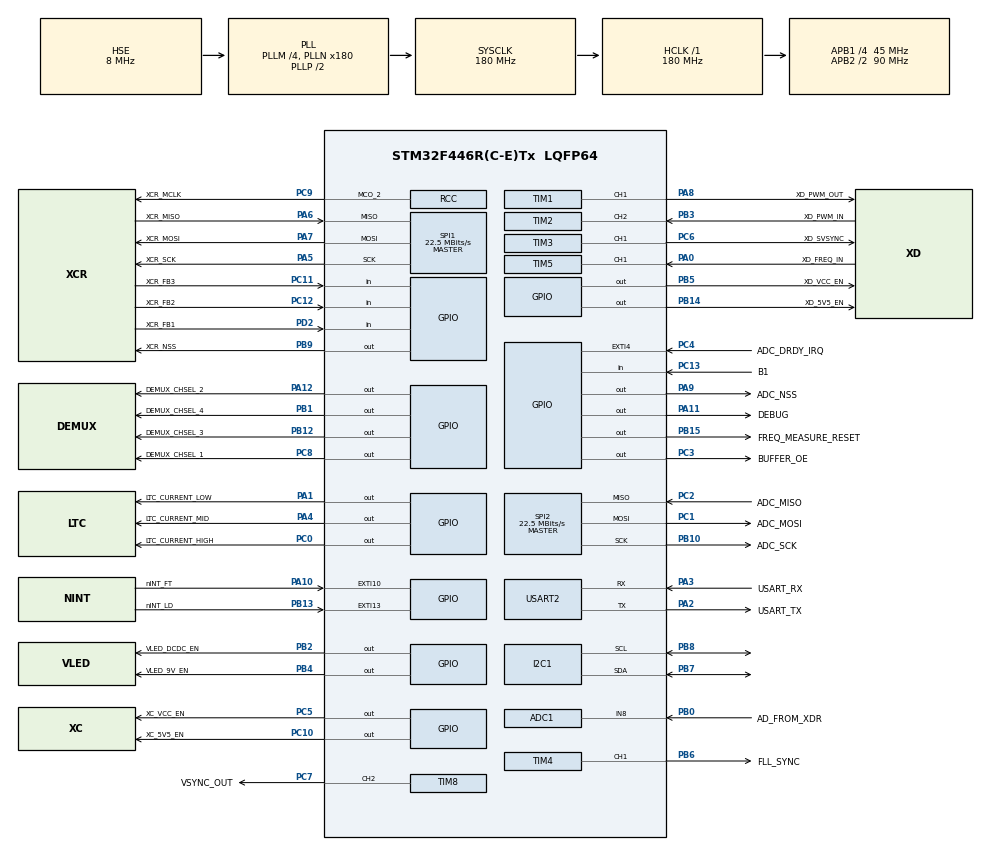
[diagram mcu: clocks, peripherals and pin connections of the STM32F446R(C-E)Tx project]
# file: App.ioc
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ADC1.Channel-0\#ChannelRegularConversion=ADC_CHANNEL_8
ADC1.NbrOfConversionFlag=1
ADC1.Rank-0\#ChannelRegularConversion=1
ADC1.SamplingTime-0\#ChannelRegularConversion=ADC_SAMPLETIME_480CYCLES
ADC1.master=1
Dma.Request0=SPI1_TX
Dma.Request1=TIM1_CH1
Dma.Request2=TIM2_CH2/CH4
Dma.Request3=TIM5_CH1
Dma.SPI1_TX.0.Direction=DMA_MEMORY_TO_PERIPH
Dma.SPI1_TX.0.FIFOMode=DMA_FIFOMODE_DISABLE
Dma.SPI1_TX.0.Instance=DMA2_Stream3
Dma.SPI1_TX.0.MemDataAlignment=DMA_MDATAALIGN_HALFWORD
Dma.SPI1_TX.0.MemInc=DMA_MINC_ENABLE
Dma.SPI1_TX.0.Mode=DMA_NORMAL
Dma.SPI1_TX.0.PeriphDataAlignment=DMA_PDATAALIGN_HALFWORD
Dma.SPI1_TX.0.PeriphInc=DMA_PINC_DISABLE
Dma.SPI1_TX.0.Priority=DMA_PRIORITY_LOW
Dma.TIM1_CH1.1.Direction=DMA_MEMORY_TO_PERIPH
Dma.TIM1_CH1.1.FIFOMode=DMA_FIFOMODE_DISABLE
Dma.TIM1_CH1.1.Instance=DMA2_Stream1
Dma.TIM1_CH1.1.MemDataAlignment=DMA_MDATAALIGN_HALFWORD
Dma.TIM1_CH1.1.MemInc=DMA_MINC_ENABLE
Dma.TIM1_CH1.1.Mode=DMA_NORMAL
Dma.TIM1_CH1.1.PeriphDataAlignment=DMA_PDATAALIGN_HALFWORD
Dma.TIM1_CH1.1.PeriphInc=DMA_PINC_DISABLE
Dma.TIM1_CH1.1.Priority=DMA_PRIORITY_LOW
Dma.TIM2_CH2/CH4.2.Direction=DMA_PERIPH_TO_MEMORY
Dma.TIM2_CH2/CH4.2.FIFOMode=DMA_FIFOMODE_DISABLE
Dma.TIM2_CH2/CH4.2.Instance=DMA1_Stream6
Dma.TIM2_CH2/CH4.2.MemDataAlignment=DMA_MDATAALIGN_HALFWORD
Dma.TIM2_CH2/CH4.2.MemInc=DMA_MINC_ENABLE
Dma.TIM2_CH2/CH4.2.Mode=DMA_NORMAL
Dma.TIM2_CH2/CH4.2.PeriphDataAlignment=DMA_PDATAALIGN_HALFWORD
Dma.TIM2_CH2/CH4.2.PeriphInc=DMA_PINC_DISABLE
Dma.TIM2_CH2/CH4.2.Priority=DMA_PRIORITY_LOW
Dma.TIM5_CH1.3.Direction=DMA_PERIPH_TO_MEMORY
Dma.TIM5_CH1.3.FIFOMode=DMA_FIFOMODE_DISABLE
Dma.TIM5_CH1.3.Instance=DMA1_Stream2
Dma.TIM5_CH1.3.MemDataAlignment=DMA_MDATAALIGN_WORD
Dma.TIM5_CH1.3.MemInc=DMA_MINC_ENABLE
Dma.TIM5_CH1.3.Mode=DMA_NORMAL
Dma.TIM5_CH1.3.PeriphDataAlignment=DMA_PDATAALIGN_WORD
Dma.TIM5_CH1.3.PeriphInc=DMA_PINC_DISABLE
Dma.TIM5_CH1.3.Priority=DMA_PRIORITY_LOW
I2C1.I2C_Mode=I2C_Fast
Mcu.Family=STM32F4
Mcu.Name=STM32F446R(C-E)Tx
Mcu.Package=LQFP64
NVIC.DMA1_Stream2_IRQn=true\:1\:0\:true\:false\:true\:false\:true\:true
NVIC.DMA1_Stream6_IRQn=true\:1\:0\:true\:false\:true\:false\:true\:true
NVIC.DMA2_Stream1_IRQn=true\:0\:0\:false\:false\:true\:false\:true\:true
NVIC.DMA2_Stream3_IRQn=true\:0\:0\:false\:false\:true\:false\:true\:true
NVIC.EXTI15_10_IRQn=true\:0\:0\:false\:false\:true\:true\:true\:true
NVIC.EXTI4_IRQn=true\:0\:0\:true\:false\:true\:true\:true\:true
NVIC.PriorityGroup=NVIC_PRIORITYGROUP_4
NVIC.TIM3_IRQn=true\:1\:0\:true\:false\:true\:true\:true\:true
NVIC.TIM8_BRK_TIM12_IRQn=true\:2\:0\:true\:false\:true\:true\:true\:true
NVIC.TIM8_UP_TIM13_IRQn=true\:1\:0\:true\:false\:true\:true\:true\:true
NVIC.USART2_IRQn=true\:3\:0\:true\:false\:true\:true\:true\:true
PA0-WKUP.GPIO_Label=XD_FREQ_IN
PA0-WKUP.GPIO_Speed=GPIO_SPEED_FREQ_VERY_HIGH
PA0-WKUP.Signal=S_TIM5_CH1
PA1.GPIO_Label=LTC_CURRENT_LOW
PA1.PinState=GPIO_PIN_SET
PA1.Signal=GPIO_Output
PA10.GPIO_Label=nINT_FT
PA10.GPIO_ModeDefaultEXTI=GPIO_MODE_IT_FALLING
PA10.GPIO_PuPd=GPIO_NOPULL
PA10.Signal=GPXTI10
PA11.GPIO_Label=DEBUG
PA11.Signal=GPIO_Output
PA12.GPIO_Label=DEMUX_CHSEL_2
PA12.PinState=GPIO_PIN_SET
PA12.Signal=GPIO_Output
PA13.GPIO_Label=TMS
PA13.Mode=Serial_Wire
PA13.Signal=SYS_JTMS-SWDIO
PA14.GPIO_Label=TCK
PA14.Mode=Serial_Wire
PA14.Signal=SYS_JTCK-SWCLK
PA2.GPIO_Label=USART_TX
PA2.GPIO_PuPd=GPIO_PULLUP
PA2.Mode=Asynchronous
PA2.Signal=USART2_TX
PA3.GPIO_Label=USART_RX
PA3.GPIO_PuPd=GPIO_PULLUP
PA3.Mode=Asynchronous
PA3.Signal=USART2_RX
PA4.GPIO_Label=LTC_CURRENT_MID
PA4.PinState=GPIO_PIN_SET
PA4.Signal=GPIO_Output
PA5.GPIO_Label=XCR_SCK
PA5.Mode=Full_Duplex_Master
PA5.Signal=SPI1_SCK
PA6.GPIO_Label=XCR_MISO
PA6.Mode=Full_Duplex_Master
PA6.Signal=SPI1_MISO
PA7.GPIO_Label=XCR_MOSI
PA7.Mode=Full_Duplex_Master
PA7.Signal=SPI1_MOSI
PA8.GPIO_Label=XD_PWM_OUT
PA8.GPIO_Speed=GPIO_SPEED_FREQ_VERY_HIGH
PA8.Signal=S_TIM1_CH1
PA9.GPIO_Label=ADC_NSS
PA9.PinState=GPIO_PIN_SET
PA9.Signal=GPIO_Output
PB0.GPIO_Label=AD_FROM_XDR
PB0.GPIO_PuPd=GPIO_NOPULL
PB0.Signal=ADCx_IN8
PB1.GPIO_Label=DEMUX_CHSEL_4
PB1.PinState=GPIO_PIN_SET
PB1.Signal=GPIO_Output
PB10.GPIO_Label=ADC_SCK
PB10.Mode=Full_Duplex_Master
PB10.Signal=SPI2_SCK
PB12.GPIO_Label=DEMUX_CHSEL_3
PB12.PinState=GPIO_PIN_SET
PB12.Signal=GPIO_Output
PB13.GPIO_Label=nINT_LD
PB13.GPIO_ModeDefaultEXTI=GPIO_MODE_IT_FALLING
PB13.GPIO_PuPd=GPIO_NOPULL
PB13.Signal=GPXTI13
PB14.GPIO_Label=XD_5V5_EN
PB14.Signal=GPIO_Output
PB15.GPIO_Label=FREQ_MEASURE_RESET
PB15.PinState=GPIO_PIN_SET
PB15.Signal=GPIO_Output
PB2.GPIO_Label=VLED_DCDC_EN
PB2.PinState=GPIO_PIN_SET
PB2.Signal=GPIO_Output
PB3.GPIO_Label=XD_PWM_IN
PB3.GPIO_PuPd=GPIO_PULLDOWN
PB3.GPIO_Speed=GPIO_SPEED_FREQ_VERY_HIGH
PB3.Signal=S_TIM2_CH2
PB4.GPIO_Label=VLED_9V_EN
PB4.PinState=GPIO_PIN_SET
PB4.Signal=GPIO_Output
PB5.GPIO_Label=XD_VCC_EN
PB5.PinState=GPIO_PIN_SET
PB5.Signal=GPIO_Output
PB6.GPIO_Label=FLL_SYNC
PB6.Signal=S_TIM4_CH1
PB7.Mode=I2C
PB7.Signal=I2C1_SDA
PB8.Mode=I2C
PB8.Signal=I2C1_SCL
PB9.GPIO_Label=XCR_NSS
PB9.PinState=GPIO_PIN_SET
PB9.Signal=GPIO_Output
PC0.GPIO_Label=LTC_CURRENT_HIGH
PC0.PinState=GPIO_PIN_SET
PC0.Signal=GPIO_Output
PC1.GPIO_Label=ADC_MOSI
PC1.Mode=Full_Duplex_Master
PC1.Signal=SPI2_MOSI
PC10.GPIO_Label=XC_5V5_EN
PC10.Signal=GPIO_Output
PC11.GPIO_Label=XCR_FB3
PC11.Signal=GPIO_Input
PC12.GPIO_Label=XCR_FB2
PC12.Signal=GPIO_Input
PC13.GPIO_Label=B1
PC13.GPIO_PuPd=GPIO_PULLUP
PC13.Signal=GPIO_Input
PC14-OSC32_IN.Mode=LSE-External-Oscillator
PC14-OSC32_IN.Signal=RCC_OSC32_IN
PC15-OSC32_OUT.Mode=LSE-External-Oscillator
PC15-OSC32_OUT.Signal=RCC_OSC32_OUT
PC2.GPIO_Label=ADC_MISO
PC2.Mode=Full_Duplex_Master
PC2.Signal=SPI2_MISO
PC3.GPIO_Label=BUFFER_OE
PC3.Signal=GPIO_Output
PC4.GPIO_Label=ADC_DRDY_IRQ
PC4.GPIO_ModeDefaultEXTI=GPIO_MODE_IT_FALLING
PC4.GPIO_PuPd=GPIO_PULLUP
PC4.Signal=GPXTI4
PC5.GPIO_Label=XC_VCC_EN
PC5.PinState=GPIO_PIN_SET
PC5.Signal=GPIO_Output
PC6.GPIO_Label=XD_SVSYNC
PC6.Signal=S_TIM3_CH1
PC7.GPIO_Label=VSYNC_OUT
PC7.Signal=S_TIM8_CH2
PC8.GPIO_Label=DEMUX_CHSEL_1
PC8.PinState=GPIO_PIN_SET
PC8.Signal=GPIO_Output
PC9.GPIO_Label=XCR_MCLK
PC9.GPIO_Speed=GPIO_SPEED_FREQ_VERY_HIGH
PC9.Mode=Clock-out-2
PC9.Signal=RCC_MCO_2
PD2.GPIO_Label=XCR_FB1
PD2.Signal=GPIO_Input
PH0-OSC_IN.Mode=HSE-External-Oscillator
PH0-OSC_IN.Signal=RCC_OSC_IN
PH1-OSC_OUT.Mode=HSE-External-Oscillator
PH1-OSC_OUT.Signal=RCC_OSC_OUT
ProjectManager.HeapSize=0x280
ProjectManager.StackSize=0x800
ProjectManager.TargetToolchain=EWARM V8.50
RCC.48MHZClocksFreq_Value=84000000
RCC.AHBFreq_Value=180000000
RCC.APB1CLKDivider=RCC_HCLK_DIV4
RCC.APB1Freq_Value=45000000
RCC.APB1TimFreq_Value=90000000
RCC.APB2CLKDivider=RCC_HCLK_DIV2
RCC.APB2Freq_Value=90000000
RCC.APB2TimFreq_Value=180000000
RCC.CortexFreq_Value=180000000
RCC.FLatency-AdvancedSettings=FLASH_LATENCY_5
RCC.HCLKFreq_Value=180000000
RCC.HSE_VALUE=8000000
RCC.HSI_VALUE=16000000
RCC.PLLI2SM=8
RCC.PLLI2SN=420
RCC.PLLI2SR=4
RCC.PLLM=4
RCC.PLLN=180
RCC.PLLSourceVirtual=RCC_PLLSOURCE_HSE
RCC.RCC_MCO2Source=RCC_MCO2SOURCE_PLLI2SCLK
RCC.RCC_MCODiv2=RCC_MCODIV_3
RCC.SYSCLKFreq_VALUE=180000000
RCC.SYSCLKSource=RCC_SYSCLKSOURCE_PLLCLK
RCC.USBFreq_Value=180000000
RCC.VCOOutputFreq_Value=360000000
SH.ADCx_IN8.0=ADC1_IN8,IN8
SH.S_TIM1_CH1.0=TIM1_CH1,PWM Generation1 CH1
SH.S_TIM2_CH2.0=TIM2_CH2,PWM_Input_2
SH.S_TIM3_CH1.0=TIM3_CH1,PWM Generation1 CH1
SH.S_TIM4_CH1.0=TIM4_CH1,PWM Generation1 CH1
SH.S_TIM5_CH1.0=TIM5_CH1,Input_Capture1_from_TI1
SH.S_TIM8_CH2.0=TIM8_CH2,PWM Generation2 CH2
SPI1.BaudRatePrescaler=SPI_BAUDRATEPRESCALER_4
SPI1.CLKPhase=SPI_PHASE_2EDGE
SPI1.CalculateBaudRate=22.5 MBits/s
SPI1.DataSize=SPI_DATASIZE_16BIT
SPI1.Direction=SPI_DIRECTION_2LINES
SPI1.Mode=SPI_MODE_MASTER
SPI1.VirtualType=VM_MASTER
SPI2.CLKPhase=SPI_PHASE_2EDGE
SPI2.CalculateBaudRate=22.5 MBits/s
SPI2.DataSize=SPI_DATASIZE_8BIT
SPI2.Direction=SPI_DIRECTION_2LINES
SPI2.Mode=SPI_MODE_MASTER
SPI2.VirtualType=VM_MASTER
TIM1.AutomaticOutput=TIM_AUTOMATICOUTPUT_ENABLE
TIM1.Channel-PWM\ Generation1\ CH1=TIM_CHANNEL_1
TIM1.Period=179
TIM12.Prescaler=89
TIM2.ICFilter_1=0
TIM2.ICFilter_2=0
TIM2.ICPolarity_1=TIM_INPUTCHANNELPOLARITY_FALLING
TIM3.Channel-PWM\ Generation1\ CH1=TIM_CHANNEL_1
TIM3.OC1Preload_PWM=DISABLE
TIM3.Period=719
TIM4.Channel-PWM\ Generation1\ CH1=TIM_CHANNEL_1
TIM4.Period=59999
TIM4.Prescaler=14
TIM4.Pulse-PWM\ Generation1\ CH1=60
TIM5.Channel-Input_Capture1_from_TI1=TIM_CHANNEL_1
TIM8.AutoReloadPreload=TIM_AUTORELOAD_PRELOAD_ENABLE
TIM8.AutomaticOutput=TIM_AUTOMATICOUTPUT_ENABLE
TIM8.Channel-PWM\ Generation2\ CH2=TIM_CHANNEL_2
TIM8.Period=49999
TIM8.Prescaler=29
TIM8.TIM_MasterOutputTrigger=TIM_TRGO_UPDATE
TIM8.TIM_MasterSlaveMode=TIM_MASTERSLAVEMODE_ENABLE
USART2.VirtualMode=VM_ASYNC
VP_TIM12_VS_ClockSourceINT.Mode=Internal
VP_TIM1_VS_ClockSourceINT.Mode=Internal
VP_TIM2_VS_ClockSourceINT.Mode=Internal
VP_TIM3_VS_ClockSourceINT.Mode=Internal
VP_TIM4_VS_ClockSourceITR.Mode=TriggerSource_ITR3
VP_TIM5_VS_ClockSourceINT.Mode=Internal
VP_TIM8_VS_ClockSourceINT.Mode=Internal
board=NUCLEO-F446RE

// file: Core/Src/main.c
/* USER CODE BEGIN Header */
/**
  ******************************************************************************
  * @file           : main.c
  * @brief          : Main program body
  ******************************************************************************
  * @attention
  *
  * Copyright (c) 2026 STMicroelectronics.
  * All rights reserved.
  *
  * This software is licensed under terms that can be found in the LICENSE file
  * in the root directory of this software component.
  * If no LICENSE file comes with this software, it is provided AS-IS.
  *
  ******************************************************************************
  */
/* USER CODE END Header */
#include "main.h"

/* USER CODE BEGIN Includes */
#include <stdbool.h>
#include <string.h>

#include "drv_comm.h"
#include "drv_gpio.h"
#include "drv_xcr24.h"
#include "drv_xdr12.h"
#include "drv_timer.h"

#include "ads124s08.h"
#include "framework.h"
#include "comm_debugging.h"
#include "ldim_conversion.h"
/* USER CODE END Includes */

/* USER CODE BEGIN PD */
#define MCU_ADC_MEASURE_COUNT             (20U)
#define MCU_ADC_VREF                      (3.3f)
#define MCU_ADC_RESOLUTION                (4095.0f)

#define MCU_TIM_INPUT_CAPTURE_SIZE        (512U)
#define MCU_INPUT_CAPTURE_START_OFS       (2U)
#define MCU_TIM_INPUT_CAPTURE_TIMEOUT_MS  (1000U)
/* USER CODE END PD */

I2C_HandleTypeDef hi2c1;

/* USER CODE BEGIN PV */
typedef struct tag_INPUT_CAPTURE_INFO
{
    uint32_t tim_cnt[MCU_TIM_INPUT_CAPTURE_SIZE];
    float tim_freq; /* Unit: Hz */
    bool start;
    bool done;
    uint32_t timeout_ms;
    uint32_t start_tick;
} input_capture_info_t;
static input_capture_info_t gt_input_capture_info;
static uint32_t gn_InternalADC;
/* USER CODE END PV */

void SystemClock_Config(void);
void PeriphCommonClock_Config(void);
static void MX_GPIO_Init(void);
static void MX_DMA_Init(void);
static void MX_USART2_UART_Init(void);
static void MX_ADC1_Init(void);
static void MX_SPI1_Init(void);
static void MX_SPI2_Init(void);
static void MX_TIM12_Init(void);
static void MX_TIM8_Init(void);
static void MX_TIM4_Init(void);
static void MX_TIM1_Init(void);
static void MX_TIM2_Init(void);
static void MX_TIM3_Init(void);
static void MX_TIM5_Init(void);
static void MX_I2C1_Init(void);
/* USER CODE BEGIN PFP */

extern void fw_run(void);

/* USER CODE END PFP */

/* USER CODE BEGIN 0 */
void sys_init(void)
{
    /* XD PWM_OUT */
    /* Set the Prescaler value */
    LL_TIM_SetPrescaler(TIM1, (uint32_t)TIM1_PRESCALER);
    /* Set the Autoreload value */
    LL_TIM_SetAutoReload(TIM1, (uint32_t)TIM1_PERIOD);

    XCR_NSS_LO();
    MCO2_DISABLE();

    xcr24_init_param();
    xdr12_init_param();

#if (XDR_EFUSE == XDR_EFUSE_SKIP)
    xdr12_trim_set_efuse_enable(false);
#elif (XDR_EFUSE == XDR_EFUSE_BURN)
    xdr12_trim_set_efuse_enable(true);
#else
    #error "XDR_EFUSE is not defined"
#endif

#if (XCR_EFUSE == XCR_EFUSE_SKIP)
    xcr24_trim_set_efuse_enable(false);
#elif (XCR_EFUSE == XCR_EFUSE_BURN)
    xcr24_trim_set_efuse_enable(true);
#else
    #error "XCR_EFUSE is not defined"
#endif
    LL_TIM_DisableARRPreload(TIM3);
    LL_TIM_OC_DisablePreload(TIM3, LL_TIM_CHANNEL_CH1);

    LL_TIM_ClearFlag_UPDATE(TIM3);
    LL_TIM_ClearFlag_UPDATE(TIM8);
    LL_TIM_ClearFlag_UPDATE(TIM12);

    __enable_irq();

    comm_init();
    ADS114S08_Init();
    ldim_block_map_init();
    ldim_block_map_print();
}

void sys_normal_mode(void)
{
}

void _system_idle(void)
{
    tim_vsync_out_process();
    comm_debugging_process();
}

void mcu_peripheral_adc_start(void)
{
    gn_InternalADC = 0U;
    LL_ADC_Enable(ADC1);
    LL_mDelay(1U);
    for (uint8_t cnt = 0U; cnt < MCU_ADC_MEASURE_COUNT; ++cnt)
    {
        LL_ADC_REG_StartConversionSWStart(ADC1);
        while(!LL_ADC_IsActiveFlag_EOCS(ADC1)) {}
        LL_ADC_ClearFlag_EOCS(ADC1);
        gn_InternalADC += LL_ADC_REG_ReadConversionData12(ADC1);
        LL_mDelay(1U);
    }

    LL_ADC_Disable(ADC1);
}

uint16_t mcu_peripheral_adc_get(void)
{
    return (uint16_t)(((float)gn_InternalADC / MCU_ADC_MEASURE_COUNT) + 0.5f);
}

float mcu_peripheral_adc_conversion_to_voltage(uint16_t adc_value)
{
    return (float)((float)adc_value / MCU_ADC_RESOLUTION * MCU_ADC_VREF);
}

void mcu_peripheral_tim_input_capture_start(void)
{
    FREQ_MEASURE_RESET_LO();

    LL_DMA_SetDataLength(DMA1, LL_DMA_STREAM_2, MCU_TIM_INPUT_CAPTURE_SIZE);
    LL_DMA_EnableStream(DMA1, LL_DMA_STREAM_2);
    LL_TIM_EnableCounter(TIM5);

    memset(gt_input_capture_info.tim_cnt, 0U, sizeof(gt_input_capture_info.tim_cnt));

    gt_input_capture_info.tim_freq = 0.0f;
    gt_input_capture_info.start = true;
    gt_input_capture_info.done = false;
    gt_input_capture_info.start_tick = get_system_tick();

    if (gt_input_capture_info.timeout_ms == 0U)
    {
        gt_input_capture_info.timeout_ms = MCU_TIM_INPUT_CAPTURE_TIMEOUT_MS;
    }
}

void mcu_peripheral_tim_input_capture_stop(void)
{
    if(true == gt_input_capture_info.start)
    {
        LL_TIM_DisableCounter(TIM5);

        FREQ_MEASURE_RESET_HI();

        gt_input_capture_info.start = false;
        gt_input_capture_info.done = true;
    }
}

float mcu_peripheral_tim_conversion_freq(void)
{
    uint32_t start = gt_input_capture_info.start_tick;
    uint32_t timeout = gt_input_capture_info.timeout_ms;

    if ((gt_input_capture_info.start == true) || (gt_input_capture_info.done == false))
    {
        if (timeout == 0U)
        {
            // wait forever
            while((gt_input_capture_info.start == true) || (gt_input_capture_info.done == false))
            {
                __NOP();
            }
        }
        else
        {
            // wait until timeout event occur
            while (((gt_input_capture_info.start == true) || (gt_input_capture_info.done == false)) && ((get_system_tick() - start) < timeout))
            {
                __NOP();
            }
            if ((gt_input_capture_info.start == true) || (gt_input_capture_info.done == false))
            {
                mcu_peripheral_tim_input_capture_stop();
                comm_UART_Printf(LOG_LV_ERROR, "\r\nInput Capture Timeout Occur!!!!");
                return 0.0f;
            }
        }
    }
    uint32_t delta = 0U;
    uint32_t counter = 0U;

    for(uint16_t i = MCU_INPUT_CAPTURE_START_OFS ; i < MCU_TIM_INPUT_CAPTURE_SIZE; ++i) // skip tim_cnt[0]
    {
        if(gt_input_capture_info.tim_cnt[i] >= gt_input_capture_info.tim_cnt[i - 1U])
        {
            delta += gt_input_capture_info.tim_cnt[i] - gt_input_capture_info.tim_cnt[i - 1U];
        }
        else
        {
            delta += (TIM5_PERIOD - gt_input_capture_info.tim_cnt[i - 1U]) + gt_input_capture_info.tim_cnt[i] + 1U;
        }

        ++counter;
    }

    if(delta > 0U)
    {
        gt_input_capture_info.tim_freq = (((float)TIM5_CLK * counter) / delta);
    }
    else
    {
        gt_input_capture_info.tim_freq = 0.0f;
    }

    return gt_input_capture_info.tim_freq;
}

/* USER CODE END 0 */

int main(void)
{

  __disable_irq();

  /* MCU Configuration--------------------------------------------------------*/

  /* Reset of all peripherals, Initializes the Flash interface and the Systick. */
  HAL_Init();

  /* Configure the system clock */
  SystemClock_Config();

  /* Configure the peripherals common clocks */
  PeriphCommonClock_Config();

  /* Initialize all configured peripherals */
  MX_GPIO_Init();
  MX_DMA_Init();
  MX_USART2_UART_Init();
  MX_ADC1_Init();
  MX_SPI1_Init();
  MX_SPI2_Init();
  MX_TIM12_Init();
  MX_TIM8_Init();
  MX_TIM4_Init();
  MX_TIM1_Init();
  MX_TIM2_Init();
  MX_TIM3_Init();
  MX_TIM5_Init();
  MX_I2C1_Init();
  /* USER CODE BEGIN 2 */

    fw_run();

  /* USER CODE END 2 */

  /* Infinite loop */
  /* USER CODE BEGIN WHILE */
  while (1)
  {
        //blu_process();

    /* USER CODE END WHILE */

  }
}

void SystemClock_Config(void)
{
  RCC_OscInitTypeDef RCC_OscInitStruct = {0};
  RCC_ClkInitTypeDef RCC_ClkInitStruct = {0};

  /** Configure the main internal regulator output voltage
  */
  __HAL_RCC_PWR_CLK_ENABLE();
  __HAL_PWR_VOLTAGESCALING_CONFIG(PWR_REGULATOR_VOLTAGE_SCALE1);

  /** Initializes the RCC Oscillators according to the specified parameters
  * in the RCC_OscInitTypeDef structure.
  */
  RCC_OscInitStruct.OscillatorType = RCC_OSCILLATORTYPE_HSE;
  RCC_OscInitStruct.HSEState = RCC_HSE_ON;
  RCC_OscInitStruct.HSIState = RCC_HSI_ON;
  RCC_OscInitStruct.HSICalibrationValue = RCC_HSICALIBRATION_DEFAULT;
  RCC_OscInitStruct.PLL.PLLState = RCC_PLL_ON;
  RCC_OscInitStruct.PLL.PLLSource = RCC_PLLSOURCE_HSE;
  RCC_OscInitStruct.PLL.PLLM = 4;
  RCC_OscInitStruct.PLL.PLLN = 180;
  RCC_OscInitStruct.PLL.PLLP = RCC_PLLP_DIV2;
  RCC_OscInitStruct.PLL.PLLQ = 2;
  RCC_OscInitStruct.PLL.PLLR = 2;
  if (HAL_RCC_OscConfig(&RCC_OscInitStruct) != HAL_OK)
  {
    Error_Handler();
  }

  /** Activate the Over-Drive mode
  */
  if (HAL_PWREx_EnableOverDrive() != HAL_OK)
  {
    Error_Handler();
  }

  /** Initializes the CPU, AHB and APB buses clocks
  */
  RCC_ClkInitStruct.ClockType = RCC_CLOCKTYPE_HCLK|RCC_CLOCKTYPE_SYSCLK
                              |RCC_CLOCKTYPE_PCLK1|RCC_CLOCKTYPE_PCLK2;
  RCC_ClkInitStruct.SYSCLKSource = RCC_SYSCLKSOURCE_PLLCLK;
  RCC_ClkInitStruct.AHBCLKDivider = RCC_SYSCLK_DIV1;
  RCC_ClkInitStruct.APB1CLKDivider = RCC_HCLK_DIV4;
  RCC_ClkInitStruct.APB2CLKDivider = RCC_HCLK_DIV2;

  if (HAL_RCC_ClockConfig(&RCC_ClkInitStruct, FLASH_LATENCY_5) != HAL_OK)
  {
    Error_Handler();
  }
  HAL_RCC_MCOConfig(RCC_MCO2, RCC_MCO2SOURCE_PLLI2SCLK, RCC_MCODIV_3);
}

void PeriphCommonClock_Config(void)
{
  RCC_PeriphCLKInitTypeDef PeriphClkInitStruct = {0};

  /** Initializes the peripherals clock
  */
  PeriphClkInitStruct.PeriphClockSelection = RCC_PERIPHCLK_PLLI2S;
  PeriphClkInitStruct.PLLI2S.PLLI2SN = 420;
  PeriphClkInitStruct.PLLI2S.PLLI2SP = RCC_PLLI2SP_DIV2;
  PeriphClkInitStruct.PLLI2S.PLLI2SM = 8;
  PeriphClkInitStruct.PLLI2S.PLLI2SR = 4;
  PeriphClkInitStruct.PLLI2S.PLLI2SQ = 2;
  PeriphClkInitStruct.PLLI2SDivQ = 1;
  if (HAL_RCCEx_PeriphCLKConfig(&PeriphClkInitStruct) != HAL_OK)
  {
    Error_Handler();
  }
}

static void MX_ADC1_Init(void)
{

  LL_ADC_InitTypeDef ADC_InitStruct = {0};
  LL_ADC_REG_InitTypeDef ADC_REG_InitStruct = {0};
  LL_ADC_CommonInitTypeDef ADC_CommonInitStruct = {0};

  LL_GPIO_InitTypeDef GPIO_InitStruct = {0};

  /* Peripheral clock enable */
  LL_APB2_GRP1_EnableClock(LL_APB2_GRP1_PERIPH_ADC1);

  LL_AHB1_GRP1_EnableClock(LL_AHB1_GRP1_PERIPH_GPIOB);
  /**ADC1 GPIO Configuration
  PB0   ------> ADC1_IN8
  */
  GPIO_InitStruct.Pin = AD_FROM_XDR_Pin;
  GPIO_InitStruct.Mode = LL_GPIO_MODE_ANALOG;
  GPIO_InitStruct.Pull = LL_GPIO_PULL_NO;
  LL_GPIO_Init(AD_FROM_XDR_GPIO_Port, &GPIO_InitStruct);

  /** Common config
  */
  ADC_InitStruct.Resolution = LL_ADC_RESOLUTION_12B;
  ADC_InitStruct.DataAlignment = LL_ADC_DATA_ALIGN_RIGHT;
  ADC_InitStruct.SequencersScanMode = LL_ADC_SEQ_SCAN_DISABLE;
  LL_ADC_Init(ADC1, &ADC_InitStruct);
  ADC_REG_InitStruct.TriggerSource = LL_ADC_REG_TRIG_SOFTWARE;
  ADC_REG_InitStruct.SequencerLength = LL_ADC_REG_SEQ_SCAN_DISABLE;
  ADC_REG_InitStruct.SequencerDiscont = LL_ADC_REG_SEQ_DISCONT_DISABLE;
  ADC_REG_InitStruct.ContinuousMode = LL_ADC_REG_CONV_SINGLE;
  ADC_REG_InitStruct.DMATransfer = LL_ADC_REG_DMA_TRANSFER_NONE;
  LL_ADC_REG_Init(ADC1, &ADC_REG_InitStruct);
  LL_ADC_REG_SetFlagEndOfConversion(ADC1, LL_ADC_REG_FLAG_EOC_UNITARY_CONV);
  ADC_CommonInitStruct.CommonClock = LL_ADC_CLOCK_SYNC_PCLK_DIV4;
  ADC_CommonInitStruct.Multimode = LL_ADC_MULTI_INDEPENDENT;
  LL_ADC_CommonInit(__LL_ADC_COMMON_INSTANCE(ADC1), &ADC_CommonInitStruct);

  /** Configure Regular Channel
  */
  LL_ADC_REG_SetSequencerRanks(ADC1, LL_ADC_REG_RANK_1, LL_ADC_CHANNEL_8);
  LL_ADC_SetChannelSamplingTime(ADC1, LL_ADC_CHANNEL_8, LL_ADC_SAMPLINGTIME_480CYCLES);

}

static void MX_I2C1_Init(void)
{

  hi2c1.Instance = I2C1;
  hi2c1.Init.ClockSpeed = 400000;
  hi2c1.Init.DutyCycle = I2C_DUTYCYCLE_2;
  hi2c1.Init.OwnAddress1 = 0;
  hi2c1.Init.AddressingMode = I2C_ADDRESSINGMODE_7BIT;
  hi2c1.Init.DualAddressMode = I2C_DUALADDRESS_DISABLE;
  hi2c1.Init.OwnAddress2 = 0;
  hi2c1.Init.GeneralCallMode = I2C_GENERALCALL_DISABLE;
  hi2c1.Init.NoStretchMode = I2C_NOSTRETCH_DISABLE;
  if (HAL_I2C_Init(&hi2c1) != HAL_OK)
  {
    Error_Handler();
  }

}

static void MX_SPI1_Init(void)
{

  LL_SPI_InitTypeDef SPI_InitStruct = {0};

  LL_GPIO_InitTypeDef GPIO_InitStruct = {0};

  /* Peripheral clock enable */
  LL_APB2_GRP1_EnableClock(LL_APB2_GRP1_PERIPH_SPI1);

  LL_AHB1_GRP1_EnableClock(LL_AHB1_GRP1_PERIPH_GPIOA);
  /**SPI1 GPIO Configuration
  PA5   ------> SPI1_SCK
  PA6   ------> SPI1_MISO
  PA7   ------> SPI1_MOSI
  */
  GPIO_InitStruct.Pin = XCR_SCK_Pin|XCR_MISO_Pin|XCR_MOSI_Pin;
  GPIO_InitStruct.Mode = LL_GPIO_MODE_ALTERNATE;
  GPIO_InitStruct.Speed = LL_GPIO_SPEED_FREQ_VERY_HIGH;
  GPIO_InitStruct.OutputType = LL_GPIO_OUTPUT_PUSHPULL;
  GPIO_InitStruct.Pull = LL_GPIO_PULL_NO;
  GPIO_InitStruct.Alternate = LL_GPIO_AF_5;
  LL_GPIO_Init(GPIOA, &GPIO_InitStruct);

  /* SPI1 DMA Init */

  /* SPI1_TX Init */
  LL_DMA_SetChannelSelection(DMA2, LL_DMA_STREAM_3, LL_DMA_CHANNEL_3);

  LL_DMA_SetDataTransferDirection(DMA2, LL_DMA_STREAM_3, LL_DMA_DIRECTION_MEMORY_TO_PERIPH);

  LL_DMA_SetStreamPriorityLevel(DMA2, LL_DMA_STREAM_3, LL_DMA_PRIORITY_LOW);

  LL_DMA_SetMode(DMA2, LL_DMA_STREAM_3, LL_DMA_MODE_NORMAL);

  LL_DMA_SetPeriphIncMode(DMA2, LL_DMA_STREAM_3, LL_DMA_PERIPH_NOINCREMENT);

  LL_DMA_SetMemoryIncMode(DMA2, LL_DMA_STREAM_3, LL_DMA_MEMORY_INCREMENT);

  LL_DMA_SetPeriphSize(DMA2, LL_DMA_STREAM_3, LL_DMA_PDATAALIGN_HALFWORD);

  LL_DMA_SetMemorySize(DMA2, LL_DMA_STREAM_3, LL_DMA_MDATAALIGN_HALFWORD);

  LL_DMA_DisableFifoMode(DMA2, LL_DMA_STREAM_3);

  /* USER CODE BEGIN SPI1_Init 1 */

    LL_DMA_SetPeriphAddress(DMA2, LL_DMA_STREAM_3, (uint32_t)(&(SPI1->DR)));
    LL_DMA_EnableIT_TC(DMA2, LL_DMA_STREAM_3);

  /* USER CODE END SPI1_Init 1 */
  /* SPI1 parameter configuration*/
  SPI_InitStruct.TransferDirection = LL_SPI_FULL_DUPLEX;
  SPI_InitStruct.Mode = LL_SPI_MODE_MASTER;
  SPI_InitStruct.DataWidth = LL_SPI_DATAWIDTH_16BIT;
  SPI_InitStruct.ClockPolarity = LL_SPI_POLARITY_LOW;
  SPI_InitStruct.ClockPhase = LL_SPI_PHASE_2EDGE;
  SPI_InitStruct.NSS = LL_SPI_NSS_SOFT;
  SPI_InitStruct.BaudRate = LL_SPI_BAUDRATEPRESCALER_DIV4;
  SPI_InitStruct.BitOrder = LL_SPI_MSB_FIRST;
  SPI_InitStruct.CRCCalculation = LL_SPI_CRCCALCULATION_DISABLE;
  SPI_InitStruct.CRCPoly = 10;
  LL_SPI_Init(SPI1, &SPI_InitStruct);
  LL_SPI_SetStandard(SPI1, LL_SPI_PROTOCOL_MOTOROLA);
  /* USER CODE BEGIN SPI1_Init 2 */

    LL_SPI_EnableDMAReq_TX(SPI1);
    LL_SPI_Enable(SPI1);

  /* USER CODE END SPI1_Init 2 */

}

static void MX_SPI2_Init(void)
{

  LL_SPI_InitTypeDef SPI_InitStruct = {0};

  LL_GPIO_InitTypeDef GPIO_InitStruct = {0};

  /* Peripheral clock enable */
  LL_APB1_GRP1_EnableClock(LL_APB1_GRP1_PERIPH_SPI2);

  LL_AHB1_GRP1_EnableClock(LL_AHB1_GRP1_PERIPH_GPIOC);
  LL_AHB1_GRP1_EnableClock(LL_AHB1_GRP1_PERIPH_GPIOB);
  /**SPI2 GPIO Configuration
  PC1   ------> SPI2_MOSI
  PC2   ------> SPI2_MISO
  PB10   ------> SPI2_SCK
  */
  GPIO_InitStruct.Pin = ADC_MOSI_Pin;
  GPIO_InitStruct.Mode = LL_GPIO_MODE_ALTERNATE;
  GPIO_InitStruct.Speed = LL_GPIO_SPEED_FREQ_VERY_HIGH;
  GPIO_InitStruct.OutputType = LL_GPIO_OUTPUT_PUSHPULL;
  GPIO_InitStruct.Pull = LL_GPIO_PULL_NO;
  GPIO_InitStruct.Alternate = LL_GPIO_AF_7;
  LL_GPIO_Init(ADC_MOSI_GPIO_Port, &GPIO_InitStruct);

  GPIO_InitStruct.Pin = ADC_MISO_Pin;
  GPIO_InitStruct.Mode = LL_GPIO_MODE_ALTERNATE;
  GPIO_InitStruct.Speed = LL_GPIO_SPEED_FREQ_VERY_HIGH;
  GPIO_InitStruct.OutputType = LL_GPIO_OUTPUT_PUSHPULL;
  GPIO_InitStruct.Pull = LL_GPIO_PULL_NO;
  GPIO_InitStruct.Alternate = LL_GPIO_AF_5;
  LL_GPIO_Init(ADC_MISO_GPIO_Port, &GPIO_InitStruct);

  GPIO_InitStruct.Pin = ADC_SCK_Pin;
  GPIO_InitStruct.Mode = LL_GPIO_MODE_ALTERNATE;
  GPIO_InitStruct.Speed = LL_GPIO_SPEED_FREQ_VERY_HIGH;
  GPIO_InitStruct.OutputType = LL_GPIO_OUTPUT_PUSHPULL;
  GPIO_InitStruct.Pull = LL_GPIO_PULL_NO;
  GPIO_InitStruct.Alternate = LL_GPIO_AF_5;
  LL_GPIO_Init(ADC_SCK_GPIO_Port, &GPIO_InitStruct);

  /* SPI2 parameter configuration*/
  SPI_InitStruct.TransferDirection = LL_SPI_FULL_DUPLEX;
  SPI_InitStruct.Mode = LL_SPI_MODE_MASTER;
  SPI_InitStruct.DataWidth = LL_SPI_DATAWIDTH_8BIT;
  SPI_InitStruct.ClockPolarity = LL_SPI_POLARITY_LOW;
  SPI_InitStruct.ClockPhase = LL_SPI_PHASE_2EDGE;
  SPI_InitStruct.NSS = LL_SPI_NSS_SOFT;
  SPI_InitStruct.BaudRate = LL_SPI_BAUDRATEPRESCALER_DIV2;
  SPI_InitStruct.BitOrder = LL_SPI_MSB_FIRST;
  SPI_InitStruct.CRCCalculation = LL_SPI_CRCCALCULATION_DISABLE;
  SPI_InitStruct.CRCPoly = 10;
  LL_SPI_Init(SPI2, &SPI_InitStruct);
  LL_SPI_SetStandard(SPI2, LL_SPI_PROTOCOL_MOTOROLA);

}

static void MX_TIM1_Init(void)
{

  LL_TIM_InitTypeDef TIM_InitStruct = {0};
  LL_TIM_OC_InitTypeDef TIM_OC_InitStruct = {0};
  LL_TIM_BDTR_InitTypeDef TIM_BDTRInitStruct = {0};

  LL_GPIO_InitTypeDef GPIO_InitStruct = {0};

  /* Peripheral clock enable */
  LL_APB2_GRP1_EnableClock(LL_APB2_GRP1_PERIPH_TIM1);

  /* TIM1 DMA Init */

  /* TIM1_CH1 Init */
  LL_DMA_SetChannelSelection(DMA2, LL_DMA_STREAM_1, LL_DMA_CHANNEL_6);

  LL_DMA_SetDataTransferDirection(DMA2, LL_DMA_STREAM_1, LL_DMA_DIRECTION_MEMORY_TO_PERIPH);

  LL_DMA_SetStreamPriorityLevel(DMA2, LL_DMA_STREAM_1, LL_DMA_PRIORITY_LOW);

  LL_DMA_SetMode(DMA2, LL_DMA_STREAM_1, LL_DMA_MODE_NORMAL);

  LL_DMA_SetPeriphIncMode(DMA2, LL_DMA_STREAM_1, LL_DMA_PERIPH_NOINCREMENT);

  LL_DMA_SetMemoryIncMode(DMA2, LL_DMA_STREAM_1, LL_DMA_MEMORY_INCREMENT);

  LL_DMA_SetPeriphSize(DMA2, LL_DMA_STREAM_1, LL_DMA_PDATAALIGN_HALFWORD);

  LL_DMA_SetMemorySize(DMA2, LL_DMA_STREAM_1, LL_DMA_MDATAALIGN_HALFWORD);

  LL_DMA_DisableFifoMode(DMA2, LL_DMA_STREAM_1);

  /* USER CODE BEGIN TIM1_Init 1 */

    LL_DMA_SetPeriphAddress(DMA2, LL_DMA_STREAM_1, (uint32_t)(&(TIM1->CCR1)));
    LL_DMA_EnableIT_TC(DMA2, LL_DMA_STREAM_1);

  /* USER CODE END TIM1_Init 1 */
  TIM_InitStruct.Prescaler = 0;
  TIM_InitStruct.CounterMode = LL_TIM_COUNTERMODE_UP;
  TIM_InitStruct.Autoreload = 179;
  TIM_InitStruct.ClockDivision = LL_TIM_CLOCKDIVISION_DIV1;
  TIM_InitStruct.RepetitionCounter = 0;
  LL_TIM_Init(TIM1, &TIM_InitStruct);
  LL_TIM_DisableARRPreload(TIM1);
  LL_TIM_SetClockSource(TIM1, LL_TIM_CLOCKSOURCE_INTERNAL);
  LL_TIM_OC_EnablePreload(TIM1, LL_TIM_CHANNEL_CH1);
  TIM_OC_InitStruct.OCMode = LL_TIM_OCMODE_PWM1;
  TIM_OC_InitStruct.OCState = LL_TIM_OCSTATE_DISABLE;
  TIM_OC_InitStruct.OCNState = LL_TIM_OCSTATE_DISABLE;
  TIM_OC_InitStruct.CompareValue = 0;
  TIM_OC_InitStruct.OCPolarity = LL_TIM_OCPOLARITY_HIGH;
  TIM_OC_InitStruct.OCNPolarity = LL_TIM_OCPOLARITY_HIGH;
  TIM_OC_InitStruct.OCIdleState = LL_TIM_OCIDLESTATE_LOW;
  TIM_OC_InitStruct.OCNIdleState = LL_TIM_OCIDLESTATE_LOW;
  LL_TIM_OC_Init(TIM1, LL_TIM_CHANNEL_CH1, &TIM_OC_InitStruct);
  LL_TIM_OC_DisableFast(TIM1, LL_TIM_CHANNEL_CH1);
  LL_TIM_SetTriggerOutput(TIM1, LL_TIM_TRGO_RESET);
  LL_TIM_DisableMasterSlaveMode(TIM1);
  TIM_BDTRInitStruct.OSSRState = LL_TIM_OSSR_DISABLE;
  TIM_BDTRInitStruct.OSSIState = LL_TIM_OSSI_DISABLE;
  TIM_BDTRInitStruct.LockLevel = LL_TIM_LOCKLEVEL_OFF;
  TIM_BDTRInitStruct.DeadTime = 0;
  TIM_BDTRInitStruct.BreakState = LL_TIM_BREAK_DISABLE;
  TIM_BDTRInitStruct.BreakPolarity = LL_TIM_BREAK_POLARITY_HIGH;
  TIM_BDTRInitStruct.AutomaticOutput = LL_TIM_AUTOMATICOUTPUT_ENABLE;
  LL_TIM_BDTR_Init(TIM1, &TIM_BDTRInitStruct);
  /* USER CODE BEGIN TIM1_Init 2 */

  LL_TIM_CC_EnableChannel(TIM1, LL_TIM_CHANNEL_CH1);
  LL_TIM_EnableDMAReq_CC1(TIM1);

  /* USER CODE END TIM1_Init 2 */
  LL_AHB1_GRP1_EnableClock(LL_AHB1_GRP1_PERIPH_GPIOA);
  /**TIM1 GPIO Configuration
  PA8   ------> TIM1_CH1
  */
  GPIO_InitStruct.Pin = XD_PWM_OUT_Pin;
  GPIO_InitStruct.Mode = LL_GPIO_MODE_ALTERNATE;
  GPIO_InitStruct.Speed = LL_GPIO_SPEED_FREQ_VERY_HIGH;
  GPIO_InitStruct.OutputType = LL_GPIO_OUTPUT_PUSHPULL;
  GPIO_InitStruct.Pull = LL_GPIO_PULL_NO;
  GPIO_InitStruct.Alternate = LL_GPIO_AF_1;
  LL_GPIO_Init(XD_PWM_OUT_GPIO_Port, &GPIO_InitStruct);

}

static void MX_TIM2_Init(void)
{

  LL_TIM_InitTypeDef TIM_InitStruct = {0};

  LL_GPIO_InitTypeDef GPIO_InitStruct = {0};

  /* Peripheral clock enable */
  LL_APB1_GRP1_EnableClock(LL_APB1_GRP1_PERIPH_TIM2);

  LL_AHB1_GRP1_EnableClock(LL_AHB1_GRP1_PERIPH_GPIOB);
  /**TIM2 GPIO Configuration
  PB3   ------> TIM2_CH2
  */
  GPIO_InitStruct.Pin = XD_PWM_IN_Pin;
  GPIO_InitStruct.Mode = LL_GPIO_MODE_ALTERNATE;
  GPIO_InitStruct.Speed = LL_GPIO_SPEED_FREQ_VERY_HIGH;
  GPIO_InitStruct.OutputType = LL_GPIO_OUTPUT_PUSHPULL;
  GPIO_InitStruct.Pull = LL_GPIO_PULL_DOWN;
  GPIO_InitStruct.Alternate = LL_GPIO_AF_1;
  LL_GPIO_Init(XD_PWM_IN_GPIO_Port, &GPIO_InitStruct);

  /* TIM2 DMA Init */

  /* TIM2_CH2_CH4 Init */
  LL_DMA_SetChannelSelection(DMA1, LL_DMA_STREAM_6, LL_DMA_CHANNEL_3);

  LL_DMA_SetDataTransferDirection(DMA1, LL_DMA_STREAM_6, LL_DMA_DIRECTION_PERIPH_TO_MEMORY);

  LL_DMA_SetStreamPriorityLevel(DMA1, LL_DMA_STREAM_6, LL_DMA_PRIORITY_LOW);

  LL_DMA_SetMode(DMA1, LL_DMA_STREAM_6, LL_DMA_MODE_NORMAL);

  LL_DMA_SetPeriphIncMode(DMA1, LL_DMA_STREAM_6, LL_DMA_PERIPH_NOINCREMENT);

  LL_DMA_SetMemoryIncMode(DMA1, LL_DMA_STREAM_6, LL_DMA_MEMORY_INCREMENT);

  LL_DMA_SetPeriphSize(DMA1, LL_DMA_STREAM_6, LL_DMA_PDATAALIGN_HALFWORD);

  LL_DMA_SetMemorySize(DMA1, LL_DMA_STREAM_6, LL_DMA_MDATAALIGN_HALFWORD);

  LL_DMA_DisableFifoMode(DMA1, LL_DMA_STREAM_6);

  /* USER CODE BEGIN TIM2_Init 1 */
    LL_DMA_SetChannelSelection(DMA1, LL_DMA_STREAM_5, LL_DMA_CHANNEL_3);
    LL_DMA_SetDataTransferDirection(DMA1, LL_DMA_STREAM_5, LL_DMA_DIRECTION_PERIPH_TO_MEMORY);
    LL_DMA_SetStreamPriorityLevel(DMA1, LL_DMA_STREAM_5, LL_DMA_PRIORITY_LOW);
    LL_DMA_SetMode(DMA1, LL_DMA_STREAM_5, LL_DMA_MODE_NORMAL);
    LL_DMA_SetPeriphIncMode(DMA1, LL_DMA_STREAM_5, LL_DMA_PERIPH_NOINCREMENT);
    LL_DMA_SetMemoryIncMode(DMA1, LL_DMA_STREAM_5, LL_DMA_MEMORY_INCREMENT);
    LL_DMA_SetPeriphSize(DMA1, LL_DMA_STREAM_5, LL_DMA_PDATAALIGN_HALFWORD);
    LL_DMA_SetMemorySize(DMA1, LL_DMA_STREAM_5, LL_DMA_MDATAALIGN_HALFWORD);
    LL_DMA_DisableFifoMode(DMA1, LL_DMA_STREAM_5);

    LL_DMA_SetPeriphAddress(DMA1, LL_DMA_STREAM_5, (uint32_t)(&(TIM2->CCR1)));   /* falling edge - pwm duty */
    LL_DMA_SetPeriphAddress(DMA1, LL_DMA_STREAM_6, (uint32_t)(&(TIM2->CCR2)));   /* rising edge - pwm frequency */

  /* USER CODE END TIM2_Init 1 */
  TIM_InitStruct.Prescaler = 0;
  TIM_InitStruct.CounterMode = LL_TIM_COUNTERMODE_UP;
  TIM_InitStruct.Autoreload = 4294967295;
  TIM_InitStruct.ClockDivision = LL_TIM_CLOCKDIVISION_DIV1;
  LL_TIM_Init(TIM2, &TIM_InitStruct);
  LL_TIM_DisableARRPreload(TIM2);
  LL_TIM_SetClockSource(TIM2, LL_TIM_CLOCKSOURCE_INTERNAL);
  LL_TIM_SetTriggerInput(TIM2, LL_TIM_TS_TI2FP2);
  LL_TIM_SetSlaveMode(TIM2, LL_TIM_SLAVEMODE_RESET);
  LL_TIM_CC_DisableChannel(TIM2, LL_TIM_CHANNEL_CH2);
  LL_TIM_IC_SetFilter(TIM2, LL_TIM_CHANNEL_CH2, LL_TIM_IC_FILTER_FDIV1);
  LL_TIM_IC_SetPolarity(TIM2, LL_TIM_CHANNEL_CH2, LL_TIM_IC_POLARITY_RISING);
  LL_TIM_DisableIT_TRIG(TIM2);
  LL_TIM_DisableDMAReq_TRIG(TIM2);
  LL_TIM_IC_SetActiveInput(TIM2, LL_TIM_CHANNEL_CH1, LL_TIM_ACTIVEINPUT_INDIRECTTI);
  LL_TIM_IC_SetPrescaler(TIM2, LL_TIM_CHANNEL_CH1, LL_TIM_ICPSC_DIV1);
  LL_TIM_IC_SetFilter(TIM2, LL_TIM_CHANNEL_CH1, LL_TIM_IC_FILTER_FDIV1);
  LL_TIM_IC_SetPolarity(TIM2, LL_TIM_CHANNEL_CH1, LL_TIM_IC_POLARITY_FALLING);
  LL_TIM_IC_SetActiveInput(TIM2, LL_TIM_CHANNEL_CH2, LL_TIM_ACTIVEINPUT_DIRECTTI);
  LL_TIM_IC_SetPrescaler(TIM2, LL_TIM_CHANNEL_CH2, LL_TIM_ICPSC_DIV1);
  LL_TIM_SetTriggerOutput(TIM2, LL_TIM_TRGO_RESET);
  LL_TIM_DisableMasterSlaveMode(TIM2);
  /* USER CODE BEGIN TIM2_Init 2 */

    LL_TIM_EnableDMAReq_CC1(TIM2);
    LL_TIM_EnableDMAReq_CC2(TIM2);

    LL_DMA_EnableIT_TC(DMA1, LL_DMA_STREAM_5);
    LL_DMA_EnableIT_TC(DMA1, LL_DMA_STREAM_6);

    /* DMA1_Stream5_IRQn interrupt configuration */
    NVIC_SetPriority(DMA1_Stream5_IRQn, NVIC_EncodePriority(NVIC_GetPriorityGrouping(),1, 0));
    NVIC_EnableIRQ(DMA1_Stream5_IRQn);

  /* USER CODE END TIM2_Init 2 */

}

static void MX_TIM3_Init(void)
{

  LL_TIM_InitTypeDef TIM_InitStruct = {0};
  LL_TIM_OC_InitTypeDef TIM_OC_InitStruct = {0};

  LL_GPIO_InitTypeDef GPIO_InitStruct = {0};

  /* Peripheral clock enable */
  LL_APB1_GRP1_EnableClock(LL_APB1_GRP1_PERIPH_TIM3);

  /* TIM3 interrupt Init */
  NVIC_SetPriority(TIM3_IRQn, NVIC_EncodePriority(NVIC_GetPriorityGrouping(),1, 0));
  NVIC_EnableIRQ(TIM3_IRQn);

  TIM_InitStruct.Prescaler = 0;
  TIM_InitStruct.CounterMode = LL_TIM_COUNTERMODE_UP;
  TIM_InitStruct.Autoreload = 719;
  TIM_InitStruct.ClockDivision = LL_TIM_CLOCKDIVISION_DIV1;
  LL_TIM_Init(TIM3, &TIM_InitStruct);
  LL_TIM_DisableARRPreload(TIM3);
  LL_TIM_SetClockSource(TIM3, LL_TIM_CLOCKSOURCE_INTERNAL);
  LL_TIM_OC_EnablePreload(TIM3, LL_TIM_CHANNEL_CH1);
  TIM_OC_InitStruct.OCMode = LL_TIM_OCMODE_PWM1;
  TIM_OC_InitStruct.OCState = LL_TIM_OCSTATE_DISABLE;
  TIM_OC_InitStruct.OCNState = LL_TIM_OCSTATE_DISABLE;
  TIM_OC_InitStruct.CompareValue = 0;
  TIM_OC_InitStruct.OCPolarity = LL_TIM_OCPOLARITY_HIGH;
  LL_TIM_OC_Init(TIM3, LL_TIM_CHANNEL_CH1, &TIM_OC_InitStruct);
  LL_TIM_OC_DisableFast(TIM3, LL_TIM_CHANNEL_CH1);
  LL_TIM_SetTriggerOutput(TIM3, LL_TIM_TRGO_RESET);
  LL_TIM_DisableMasterSlaveMode(TIM3);
  LL_TIM_OC_DisablePreload(TIM3, LL_TIM_CHANNEL_CH1);
  /* USER CODE BEGIN TIM3_Init 2 */

    LL_TIM_CC_EnableChannel(TIM3, LL_TIM_CHANNEL_CH1);
    LL_TIM_EnableIT_UPDATE(TIM3);

  /* USER CODE END TIM3_Init 2 */
  LL_AHB1_GRP1_EnableClock(LL_AHB1_GRP1_PERIPH_GPIOC);
  /**TIM3 GPIO Configuration
  PC6   ------> TIM3_CH1
  */
  GPIO_InitStruct.Pin = XD_SVSYNC_Pin;
  GPIO_InitStruct.Mode = LL_GPIO_MODE_ALTERNATE;
  GPIO_InitStruct.Speed = LL_GPIO_SPEED_FREQ_LOW;
  GPIO_InitStruct.OutputType = LL_GPIO_OUTPUT_PUSHPULL;
  GPIO_InitStruct.Pull = LL_GPIO_PULL_NO;
  GPIO_InitStruct.Alternate = LL_GPIO_AF_2;
  LL_GPIO_Init(XD_SVSYNC_GPIO_Port, &GPIO_InitStruct);

}

static void MX_TIM4_Init(void)
{

  LL_TIM_InitTypeDef TIM_InitStruct = {0};
  LL_TIM_OC_InitTypeDef TIM_OC_InitStruct = {0};

  LL_GPIO_InitTypeDef GPIO_InitStruct = {0};

  /* Peripheral clock enable */
  LL_APB1_GRP1_EnableClock(LL_APB1_GRP1_PERIPH_TIM4);

  TIM_InitStruct.Prescaler = 14;
  TIM_InitStruct.CounterMode = LL_TIM_COUNTERMODE_UP;
  TIM_InitStruct.Autoreload = 59999;
  TIM_InitStruct.ClockDivision = LL_TIM_CLOCKDIVISION_DIV1;
  LL_TIM_Init(TIM4, &TIM_InitStruct);
  LL_TIM_DisableARRPreload(TIM4);
  LL_TIM_OC_EnablePreload(TIM4, LL_TIM_CHANNEL_CH1);
  TIM_OC_InitStruct.OCMode = LL_TIM_OCMODE_PWM1;
  TIM_OC_InitStruct.OCState = LL_TIM_OCSTATE_DISABLE;
  TIM_OC_InitStruct.OCNState = LL_TIM_OCSTATE_DISABLE;
  TIM_OC_InitStruct.CompareValue = 60;
  TIM_OC_InitStruct.OCPolarity = LL_TIM_OCPOLARITY_HIGH;
  LL_TIM_OC_Init(TIM4, LL_TIM_CHANNEL_CH1, &TIM_OC_InitStruct);
  LL_TIM_OC_DisableFast(TIM4, LL_TIM_CHANNEL_CH1);
  LL_TIM_SetTriggerInput(TIM4, LL_TIM_TS_ITR3);
  LL_TIM_SetSlaveMode(TIM4, LL_TIM_SLAVEMODE_DISABLED);
  LL_TIM_DisableIT_TRIG(TIM4);
  LL_TIM_DisableDMAReq_TRIG(TIM4);
  LL_TIM_SetTriggerOutput(TIM4, LL_TIM_TRGO_RESET);
  LL_TIM_DisableMasterSlaveMode(TIM4);
  LL_AHB1_GRP1_EnableClock(LL_AHB1_GRP1_PERIPH_GPIOB);
  /**TIM4 GPIO Configuration
  PB6   ------> TIM4_CH1
  */
  GPIO_InitStruct.Pin = FLL_SYNC_Pin;
  GPIO_InitStruct.Mode = LL_GPIO_MODE_ALTERNATE;
  GPIO_InitStruct.Speed = LL_GPIO_SPEED_FREQ_LOW;
  GPIO_InitStruct.OutputType = LL_GPIO_OUTPUT_PUSHPULL;
  GPIO_InitStruct.Pull = LL_GPIO_PULL_NO;
  GPIO_InitStruct.Alternate = LL_GPIO_AF_2;
  LL_GPIO_Init(FLL_SYNC_GPIO_Port, &GPIO_InitStruct);

}

static void MX_TIM5_Init(void)
{

  LL_TIM_InitTypeDef TIM_InitStruct = {0};

  LL_GPIO_InitTypeDef GPIO_InitStruct = {0};

  /* Peripheral clock enable */
  LL_APB1_GRP1_EnableClock(LL_APB1_GRP1_PERIPH_TIM5);

  LL_AHB1_GRP1_EnableClock(LL_AHB1_GRP1_PERIPH_GPIOA);
  /**TIM5 GPIO Configuration
  PA0-WKUP   ------> TIM5_CH1
  */
  GPIO_InitStruct.Pin = XD_FREQ_IN_Pin;
  GPIO_InitStruct.Mode = LL_GPIO_MODE_ALTERNATE;
  GPIO_InitStruct.Speed = LL_GPIO_SPEED_FREQ_VERY_HIGH;
  GPIO_InitStruct.OutputType = LL_GPIO_OUTPUT_PUSHPULL;
  GPIO_InitStruct.Pull = LL_GPIO_PULL_NO;
  GPIO_InitStruct.Alternate = LL_GPIO_AF_2;
  LL_GPIO_Init(XD_FREQ_IN_GPIO_Port, &GPIO_InitStruct);

  /* TIM5 DMA Init */

  /* TIM5_CH1 Init */
  LL_DMA_SetChannelSelection(DMA1, LL_DMA_STREAM_2, LL_DMA_CHANNEL_6);

  LL_DMA_SetDataTransferDirection(DMA1, LL_DMA_STREAM_2, LL_DMA_DIRECTION_PERIPH_TO_MEMORY);

  LL_DMA_SetStreamPriorityLevel(DMA1, LL_DMA_STREAM_2, LL_DMA_PRIORITY_LOW);

  LL_DMA_SetMode(DMA1, LL_DMA_STREAM_2, LL_DMA_MODE_NORMAL);

  LL_DMA_SetPeriphIncMode(DMA1, LL_DMA_STREAM_2, LL_DMA_PERIPH_NOINCREMENT);

  LL_DMA_SetMemoryIncMode(DMA1, LL_DMA_STREAM_2, LL_DMA_MEMORY_INCREMENT);

  LL_DMA_SetPeriphSize(DMA1, LL_DMA_STREAM_2, LL_DMA_PDATAALIGN_WORD);

  LL_DMA_SetMemorySize(DMA1, LL_DMA_STREAM_2, LL_DMA_MDATAALIGN_WORD);

  LL_DMA_DisableFifoMode(DMA1, LL_DMA_STREAM_2);

  TIM_InitStruct.Prescaler = 0;
  TIM_InitStruct.CounterMode = LL_TIM_COUNTERMODE_UP;
  TIM_InitStruct.Autoreload = 4294967295;
  TIM_InitStruct.ClockDivision = LL_TIM_CLOCKDIVISION_DIV1;
  LL_TIM_Init(TIM5, &TIM_InitStruct);
  LL_TIM_DisableARRPreload(TIM5);
  LL_TIM_SetClockSource(TIM5, LL_TIM_CLOCKSOURCE_INTERNAL);
  LL_TIM_SetTriggerOutput(TIM5, LL_TIM_TRGO_RESET);
  LL_TIM_DisableMasterSlaveMode(TIM5);
  LL_TIM_IC_SetActiveInput(TIM5, LL_TIM_CHANNEL_CH1, LL_TIM_ACTIVEINPUT_DIRECTTI);
  LL_TIM_IC_SetPrescaler(TIM5, LL_TIM_CHANNEL_CH1, LL_TIM_ICPSC_DIV1);
  LL_TIM_IC_SetFilter(TIM5, LL_TIM_CHANNEL_CH1, LL_TIM_IC_FILTER_FDIV1);
  LL_TIM_IC_SetPolarity(TIM5, LL_TIM_CHANNEL_CH1, LL_TIM_IC_POLARITY_RISING);
  /* USER CODE BEGIN TIM5_Init 2 */

    LL_TIM_EnableDMAReq_CC1(TIM5);
    LL_TIM_CC_EnableChannel(TIM5, LL_TIM_CHANNEL_CH1);

    LL_DMA_EnableIT_TC(DMA1, LL_DMA_STREAM_2);
    //LL_DMA_EnableIT_TE(DMA1, LL_DMA_STREAM_2);

    LL_DMA_SetPeriphAddress(DMA1, LL_DMA_STREAM_2, (uint32_t)(&(TIM5->CCR1)));
    LL_DMA_SetMemoryAddress(DMA1, LL_DMA_STREAM_2, (uint32_t)gt_input_capture_info.tim_cnt);
  /* USER CODE END TIM5_Init 2 */

}

static void MX_TIM8_Init(void)
{

  LL_TIM_InitTypeDef TIM_InitStruct = {0};
  LL_TIM_OC_InitTypeDef TIM_OC_InitStruct = {0};
  LL_TIM_BDTR_InitTypeDef TIM_BDTRInitStruct = {0};

  LL_GPIO_InitTypeDef GPIO_InitStruct = {0};

  /* Peripheral clock enable */
  LL_APB2_GRP1_EnableClock(LL_APB2_GRP1_PERIPH_TIM8);

  /* TIM8 interrupt Init */
  NVIC_SetPriority(TIM8_BRK_TIM12_IRQn, NVIC_EncodePriority(NVIC_GetPriorityGrouping(),2, 0));
  NVIC_EnableIRQ(TIM8_BRK_TIM12_IRQn);
  NVIC_SetPriority(TIM8_UP_TIM13_IRQn, NVIC_EncodePriority(NVIC_GetPriorityGrouping(),1, 0));
  NVIC_EnableIRQ(TIM8_UP_TIM13_IRQn);

  TIM_InitStruct.Prescaler = 29;
  TIM_InitStruct.CounterMode = LL_TIM_COUNTERMODE_UP;
  TIM_InitStruct.Autoreload = 49999;
  TIM_InitStruct.ClockDivision = LL_TIM_CLOCKDIVISION_DIV1;
  TIM_InitStruct.RepetitionCounter = 0;
  LL_TIM_Init(TIM8, &TIM_InitStruct);
  LL_TIM_EnableARRPreload(TIM8);
  LL_TIM_SetClockSource(TIM8, LL_TIM_CLOCKSOURCE_INTERNAL);
  LL_TIM_OC_EnablePreload(TIM8, LL_TIM_CHANNEL_CH2);
  TIM_OC_InitStruct.OCMode = LL_TIM_OCMODE_PWM1;
  TIM_OC_InitStruct.OCState = LL_TIM_OCSTATE_DISABLE;
  TIM_OC_InitStruct.OCNState = LL_TIM_OCSTATE_DISABLE;
  TIM_OC_InitStruct.CompareValue = 0;
  TIM_OC_InitStruct.OCPolarity = LL_TIM_OCPOLARITY_HIGH;
  TIM_OC_InitStruct.OCNPolarity = LL_TIM_OCPOLARITY_HIGH;
  TIM_OC_InitStruct.OCIdleState = LL_TIM_OCIDLESTATE_LOW;
  TIM_OC_InitStruct.OCNIdleState = LL_TIM_OCIDLESTATE_LOW;
  LL_TIM_OC_Init(TIM8, LL_TIM_CHANNEL_CH2, &TIM_OC_InitStruct);
  LL_TIM_OC_DisableFast(TIM8, LL_TIM_CHANNEL_CH2);
  LL_TIM_SetTriggerOutput(TIM8, LL_TIM_TRGO_UPDATE);
  LL_TIM_EnableMasterSlaveMode(TIM8);
  TIM_BDTRInitStruct.OSSRState = LL_TIM_OSSR_DISABLE;
  TIM_BDTRInitStruct.OSSIState = LL_TIM_OSSI_DISABLE;
  TIM_BDTRInitStruct.LockLevel = LL_TIM_LOCKLEVEL_OFF;
  TIM_BDTRInitStruct.DeadTime = 0;
  TIM_BDTRInitStruct.BreakState = LL_TIM_BREAK_DISABLE;
  TIM_BDTRInitStruct.BreakPolarity = LL_TIM_BREAK_POLARITY_HIGH;
  TIM_BDTRInitStruct.AutomaticOutput = LL_TIM_AUTOMATICOUTPUT_ENABLE;
  LL_TIM_BDTR_Init(TIM8, &TIM_BDTRInitStruct);
  /* USER CODE BEGIN TIM8_Init 2 */

    LL_TIM_CC_EnableChannel(TIM8, LL_TIM_CHANNEL_CH2);
    LL_TIM_EnableIT_UPDATE(TIM8);

  /* USER CODE END TIM8_Init 2 */
  LL_AHB1_GRP1_EnableClock(LL_AHB1_GRP1_PERIPH_GPIOC);
  /**TIM8 GPIO Configuration
  PC7   ------> TIM8_CH2
  */
  GPIO_InitStruct.Pin = VSYNC_OUT_Pin;
  GPIO_InitStruct.Mode = LL_GPIO_MODE_ALTERNATE;
  GPIO_InitStruct.Speed = LL_GPIO_SPEED_FREQ_LOW;
  GPIO_InitStruct.OutputType = LL_GPIO_OUTPUT_PUSHPULL;
  GPIO_InitStruct.Pull = LL_GPIO_PULL_NO;
  GPIO_InitStruct.Alternate = LL_GPIO_AF_3;
  LL_GPIO_Init(VSYNC_OUT_GPIO_Port, &GPIO_InitStruct);

}

static void MX_TIM12_Init(void)
{

  LL_TIM_InitTypeDef TIM_InitStruct = {0};

  /* Peripheral clock enable */
  LL_APB1_GRP1_EnableClock(LL_APB1_GRP1_PERIPH_TIM12);

  /* TIM12 interrupt Init */
  NVIC_SetPriority(TIM8_BRK_TIM12_IRQn, NVIC_EncodePriority(NVIC_GetPriorityGrouping(),2, 0));
  NVIC_EnableIRQ(TIM8_BRK_TIM12_IRQn);

  TIM_InitStruct.Prescaler = 89;
  TIM_InitStruct.CounterMode = LL_TIM_COUNTERMODE_UP;
  TIM_InitStruct.Autoreload = 65535;
  TIM_InitStruct.ClockDivision = LL_TIM_CLOCKDIVISION_DIV1;
  LL_TIM_Init(TIM12, &TIM_InitStruct);
  LL_TIM_DisableARRPreload(TIM12);
  LL_TIM_SetClockSource(TIM12, LL_TIM_CLOCKSOURCE_INTERNAL);

}

static void MX_USART2_UART_Init(void)
{

  LL_USART_InitTypeDef USART_InitStruct = {0};

  LL_GPIO_InitTypeDef GPIO_InitStruct = {0};

  /* Peripheral clock enable */
  LL_APB1_GRP1_EnableClock(LL_APB1_GRP1_PERIPH_USART2);

  LL_AHB1_GRP1_EnableClock(LL_AHB1_GRP1_PERIPH_GPIOA);
  /**USART2 GPIO Configuration
  PA2   ------> USART2_TX
  PA3   ------> USART2_RX
  */
  GPIO_InitStruct.Pin = USART_TX_Pin|USART_RX_Pin;
  GPIO_InitStruct.Mode = LL_GPIO_MODE_ALTERNATE;
  GPIO_InitStruct.Speed = LL_GPIO_SPEED_FREQ_VERY_HIGH;
  GPIO_InitStruct.OutputType = LL_GPIO_OUTPUT_PUSHPULL;
  GPIO_InitStruct.Pull = LL_GPIO_PULL_UP;
  GPIO_InitStruct.Alternate = LL_GPIO_AF_7;
  LL_GPIO_Init(GPIOA, &GPIO_InitStruct);

  /* USART2 interrupt Init */
  NVIC_SetPriority(USART2_IRQn, NVIC_EncodePriority(NVIC_GetPriorityGrouping(),3, 0));
  NVIC_EnableIRQ(USART2_IRQn);

  USART_InitStruct.BaudRate = 115200;
  USART_InitStruct.DataWidth = LL_USART_DATAWIDTH_8B;
  USART_InitStruct.StopBits = LL_USART_STOPBITS_1;
  USART_InitStruct.Parity = LL_USART_PARITY_NONE;
  USART_InitStruct.TransferDirection = LL_USART_DIRECTION_TX_RX;
  USART_InitStruct.HardwareFlowControl = LL_USART_HWCONTROL_NONE;
  USART_InitStruct.OverSampling = LL_USART_OVERSAMPLING_16;
  LL_USART_Init(USART2, &USART_InitStruct);
  LL_USART_ConfigAsyncMode(USART2);
  LL_USART_Enable(USART2);
  /* USER CODE BEGIN USART2_Init 2 */

    /* USART RX */
    LL_USART_EnableIT_RXNE(USART2);
    LL_USART_EnableIT_ERROR(USART2);

  /* USER CODE END USART2_Init 2 */

}

static void MX_DMA_Init(void)
{

  /* Init with LL driver */
  /* DMA controller clock enable */
  LL_AHB1_GRP1_EnableClock(LL_AHB1_GRP1_PERIPH_DMA2);
  LL_AHB1_GRP1_EnableClock(LL_AHB1_GRP1_PERIPH_DMA1);

  /* DMA interrupt init */
  /* DMA1_Stream2_IRQn interrupt configuration */
  NVIC_SetPriority(DMA1_Stream2_IRQn, NVIC_EncodePriority(NVIC_GetPriorityGrouping(),1, 0));
  NVIC_EnableIRQ(DMA1_Stream2_IRQn);
  /* DMA1_Stream6_IRQn interrupt configuration */
  NVIC_SetPriority(DMA1_Stream6_IRQn, NVIC_EncodePriority(NVIC_GetPriorityGrouping(),1, 0));
  NVIC_EnableIRQ(DMA1_Stream6_IRQn);
  /* DMA2_Stream1_IRQn interrupt configuration */
  NVIC_SetPriority(DMA2_Stream1_IRQn, NVIC_EncodePriority(NVIC_GetPriorityGrouping(),0, 0));
  NVIC_EnableIRQ(DMA2_Stream1_IRQn);
  /* DMA2_Stream3_IRQn interrupt configuration */
  NVIC_SetPriority(DMA2_Stream3_IRQn, NVIC_EncodePriority(NVIC_GetPriorityGrouping(),0, 0));
  NVIC_EnableIRQ(DMA2_Stream3_IRQn);

}

static void MX_GPIO_Init(void)
{
  LL_EXTI_InitTypeDef EXTI_InitStruct = {0};
  LL_GPIO_InitTypeDef GPIO_InitStruct = {0};

  /* GPIO Ports Clock Enable */
  LL_AHB1_GRP1_EnableClock(LL_AHB1_GRP1_PERIPH_GPIOC);
  LL_AHB1_GRP1_EnableClock(LL_AHB1_GRP1_PERIPH_GPIOH);
  LL_AHB1_GRP1_EnableClock(LL_AHB1_GRP1_PERIPH_GPIOA);
  LL_AHB1_GRP1_EnableClock(LL_AHB1_GRP1_PERIPH_GPIOB);
  LL_AHB1_GRP1_EnableClock(LL_AHB1_GRP1_PERIPH_GPIOD);

  /**/
  LL_GPIO_SetOutputPin(GPIOC, LTC_CURRENT_HIGH_Pin|XC_VCC_EN_Pin|DEMUX_CHSEL_1_Pin);

  /**/
  LL_GPIO_SetOutputPin(GPIOA, LTC_CURRENT_LOW_Pin|LTC_CURRENT_MID_Pin|ADC_NSS_Pin|DEMUX_CHSEL_2_Pin);

  /**/
  LL_GPIO_SetOutputPin(GPIOB, DEMUX_CHSEL_4_Pin|VLED_DCDC_EN_Pin|DEMUX_CHSEL_3_Pin|FREQ_MEASURE_RESET_Pin
                          |VLED_9V_EN_Pin|XD_VCC_EN_Pin|XCR_NSS_Pin);

  /**/
  LL_GPIO_ResetOutputPin(GPIOC, BUFFER_OE_Pin|XC_5V5_EN_Pin);

  /**/
  LL_GPIO_ResetOutputPin(XD_5V5_EN_GPIO_Port, XD_5V5_EN_Pin);

  /**/
  LL_GPIO_ResetOutputPin(DEBUG_GPIO_Port, DEBUG_Pin);

  /**/
  GPIO_InitStruct.Pin = B1_Pin;
  GPIO_InitStruct.Mode = LL_GPIO_MODE_INPUT;
  GPIO_InitStruct.Pull = LL_GPIO_PULL_UP;
  LL_GPIO_Init(B1_GPIO_Port, &GPIO_InitStruct);

  /**/
  GPIO_InitStruct.Pin = LTC_CURRENT_HIGH_Pin|BUFFER_OE_Pin|XC_VCC_EN_Pin|DEMUX_CHSEL_1_Pin
                          |XC_5V5_EN_Pin;
  GPIO_InitStruct.Mode = LL_GPIO_MODE_OUTPUT;
  GPIO_InitStruct.Speed = LL_GPIO_SPEED_FREQ_LOW;
  GPIO_InitStruct.OutputType = LL_GPIO_OUTPUT_PUSHPULL;
  GPIO_InitStruct.Pull = LL_GPIO_PULL_NO;
  LL_GPIO_Init(GPIOC, &GPIO_InitStruct);

  /**/
  GPIO_InitStruct.Pin = LTC_CURRENT_LOW_Pin|LTC_CURRENT_MID_Pin|ADC_NSS_Pin|DEBUG_Pin
                          |DEMUX_CHSEL_2_Pin;
  GPIO_InitStruct.Mode = LL_GPIO_MODE_OUTPUT;
  GPIO_InitStruct.Speed = LL_GPIO_SPEED_FREQ_LOW;
  GPIO_InitStruct.OutputType = LL_GPIO_OUTPUT_PUSHPULL;
  GPIO_InitStruct.Pull = LL_GPIO_PULL_NO;
  LL_GPIO_Init(GPIOA, &GPIO_InitStruct);

  /**/
  GPIO_InitStruct.Pin = DEMUX_CHSEL_4_Pin|VLED_DCDC_EN_Pin|DEMUX_CHSEL_3_Pin|XD_5V5_EN_Pin
                          |FREQ_MEASURE_RESET_Pin|VLED_9V_EN_Pin|XD_VCC_EN_Pin|XCR_NSS_Pin;
  GPIO_InitStruct.Mode = LL_GPIO_MODE_OUTPUT;
  GPIO_InitStruct.Speed = LL_GPIO_SPEED_FREQ_LOW;
  GPIO_InitStruct.OutputType = LL_GPIO_OUTPUT_PUSHPULL;
  GPIO_InitStruct.Pull = LL_GPIO_PULL_NO;
  LL_GPIO_Init(GPIOB, &GPIO_InitStruct);

  /**/
  GPIO_InitStruct.Pin = XCR_MCLK_Pin;
  GPIO_InitStruct.Mode = LL_GPIO_MODE_ALTERNATE;
  GPIO_InitStruct.Speed = LL_GPIO_SPEED_FREQ_VERY_HIGH;
  GPIO_InitStruct.OutputType = LL_GPIO_OUTPUT_PUSHPULL;
  GPIO_InitStruct.Pull = LL_GPIO_PULL_NO;
  GPIO_InitStruct.Alternate = LL_GPIO_AF_0;
  LL_GPIO_Init(XCR_MCLK_GPIO_Port, &GPIO_InitStruct);

  /**/
  GPIO_InitStruct.Pin = XCR_FB3_Pin|XCR_FB2_Pin;
  GPIO_InitStruct.Mode = LL_GPIO_MODE_INPUT;
  GPIO_InitStruct.Pull = LL_GPIO_PULL_NO;
  LL_GPIO_Init(GPIOC, &GPIO_InitStruct);

  /**/
  GPIO_InitStruct.Pin = XCR_FB1_Pin;
  GPIO_InitStruct.Mode = LL_GPIO_MODE_INPUT;
  GPIO_InitStruct.Pull = LL_GPIO_PULL_NO;
  LL_GPIO_Init(XCR_FB1_GPIO_Port, &GPIO_InitStruct);

  /**/
  LL_SYSCFG_SetEXTISource(LL_SYSCFG_EXTI_PORTC, LL_SYSCFG_EXTI_LINE4);

  /**/
  LL_SYSCFG_SetEXTISource(LL_SYSCFG_EXTI_PORTB, LL_SYSCFG_EXTI_LINE13);

  /**/
  LL_SYSCFG_SetEXTISource(LL_SYSCFG_EXTI_PORTA, LL_SYSCFG_EXTI_LINE10);

  /**/
  EXTI_InitStruct.Line_0_31 = LL_EXTI_LINE_4;
  EXTI_InitStruct.LineCommand = ENABLE;
  EXTI_InitStruct.Mode = LL_EXTI_MODE_IT;
  EXTI_InitStruct.Trigger = LL_EXTI_TRIGGER_FALLING;
  LL_EXTI_Init(&EXTI_InitStruct);

  /**/
  EXTI_InitStruct.Line_0_31 = LL_EXTI_LINE_13;
  EXTI_InitStruct.LineCommand = ENABLE;
  EXTI_InitStruct.Mode = LL_EXTI_MODE_IT;
  EXTI_InitStruct.Trigger = LL_EXTI_TRIGGER_FALLING;
  LL_EXTI_Init(&EXTI_InitStruct);

  /**/
  EXTI_InitStruct.Line_0_31 = LL_EXTI_LINE_10;
  EXTI_InitStruct.LineCommand = ENABLE;
  EXTI_InitStruct.Mode = LL_EXTI_MODE_IT;
  EXTI_InitStruct.Trigger = LL_EXTI_TRIGGER_FALLING;
  LL_EXTI_Init(&EXTI_InitStruct);

  /**/
  LL_GPIO_SetPinPull(ADC_DRDY_IRQ_GPIO_Port, ADC_DRDY_IRQ_Pin, LL_GPIO_PULL_UP);

  /**/
  LL_GPIO_SetPinPull(nINT_LD_GPIO_Port, nINT_LD_Pin, LL_GPIO_PULL_NO);

  /**/
  LL_GPIO_SetPinPull(nINT_FT_GPIO_Port, nINT_FT_Pin, LL_GPIO_PULL_NO);

  /**/
  LL_GPIO_SetPinMode(ADC_DRDY_IRQ_GPIO_Port, ADC_DRDY_IRQ_Pin, LL_GPIO_MODE_INPUT);

  /**/
  LL_GPIO_SetPinMode(nINT_LD_GPIO_Port, nINT_LD_Pin, LL_GPIO_MODE_INPUT);

  /**/
  LL_GPIO_SetPinMode(nINT_FT_GPIO_Port, nINT_FT_Pin, LL_GPIO_MODE_INPUT);

  /* EXTI interrupt init*/
  NVIC_SetPriority(EXTI4_IRQn, NVIC_EncodePriority(NVIC_GetPriorityGrouping(),0, 0));
  NVIC_EnableIRQ(EXTI4_IRQn);
  NVIC_SetPriority(EXTI15_10_IRQn, NVIC_EncodePriority(NVIC_GetPriorityGrouping(),0, 0));
  NVIC_EnableIRQ(EXTI15_10_IRQn);

}

void Error_Handler(void)
{
  __disable_irq();
  while (1)
  {
  }
}
